# f29h85x_rtdma_diag_regs register map
Vendor: Texas Instruments
Peripheral module from a debugger description file (folder HSM).
Registers are 32-bit, read-write, no defined reset value unless marked. A register's access mark holds for its fields unless they carry their own. Offsets are as the file gives them; lines under a group give offsets from that group; [hi:lo] are bit positions; {n}, {i} and the like mark numbered series; 'fields as' and 'values as' point back to an identical list; <NAME> marks a mode.

## RTDMA_DIAG_REGS — RTDMA DIAG Registers
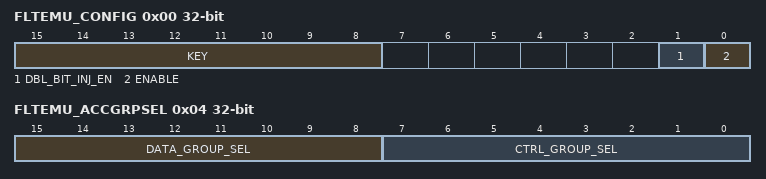
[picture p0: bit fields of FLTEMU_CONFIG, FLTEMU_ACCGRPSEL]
0x00 FLTEMU_CONFIG — Fault emulation configuration registerr
  [15:8] KEY — Write Key
  [1] DBL_BIT_INJ_EN — Double bit injection enable
  [0] ENABLE — Fault emulation enable
0x04 FLTEMU_ACCGRPSEL — Fault emulation access information group selection register
  [15:8] DATA_GROUP_SEL — DATA READ1 control information bus selection
  [7:0] CTRL_GROUP_SEL — CTRL group selection
0x08 FLTEMU_BITSEL — Fault emulation bitsel
  [6:0] BITSEL — Fault emulation bit selection
0x0C FLTEMU_ADDR — Fault emulation access address register
  [31:0] ADDR — Fault emulation address
